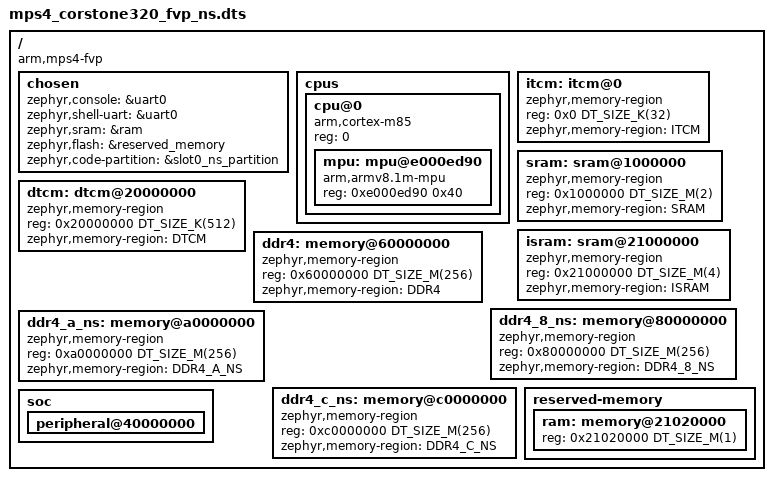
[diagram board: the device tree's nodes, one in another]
/*
 * Copyright 2025 Arm Limited and/or its affiliates <open-source-office@arm.com>
 *
 * SPDX-License-Identifier: Apache-2.0
 */

/dts-v1/;

#include <arm/armv8.1-m.dtsi>
#include <zephyr/dt-bindings/i2c/i2c.h>
#include <zephyr/dt-bindings/input/input-event-codes.h>
#include <mem.h>

#include "mps4_common_ns.dtsi"

/ {
	compatible = "arm,mps4-fvp";
	#address-cells = <1>;
	#size-cells = <1>;

	chosen {
		zephyr,console = &uart0;
		zephyr,shell-uart = &uart0;
		zephyr,sram = &ram;
		zephyr,flash = &reserved_memory;
		zephyr,code-partition = &slot0_ns_partition;
	};

	cpus {
		#address-cells = <1>;
		#size-cells = <0>;

		cpu@0 {
			device_type = "cpu";
			compatible = "arm,cortex-m85";
			reg = <0>;
			#address-cells = <1>;
			#size-cells = <1>;

			mpu: mpu@e000ed90 {
				compatible = "arm,armv8.1m-mpu";
				reg = <0xe000ed90 0x40>;
			};
		};
	};

	/* We utilize the secure addresses, if you subtract 0x10000000
	 * you'll get the non-secure alias
	 */
	itcm: itcm@0 {
		compatible = "zephyr,memory-region";
		reg = <0x0 DT_SIZE_K(32)>;
		zephyr,memory-region = "ITCM";
	};

	sram: sram@1000000 {
		compatible = "zephyr,memory-region", "mmio-sram";
		reg = <0x1000000 DT_SIZE_M(2)>;
		zephyr,memory-region = "SRAM";
	};

	dtcm: dtcm@20000000 {
		compatible = "zephyr,memory-region";
		reg = <0x20000000 DT_SIZE_K(512)>;
		zephyr,memory-region = "DTCM";
	};

	isram: sram@21000000 {
		compatible = "zephyr,memory-region", "mmio-sram";
		reg = <0x21000000 DT_SIZE_M(4)>;
		zephyr,memory-region = "ISRAM";
	};

	/* The DDR4 node and zephyr,memory-region follow the naming convention
	 * ddr4_$IDAUID_$SECURITY_FLAG except for the default region of board
	 * which is named as "DDR4" to be compatible with existing
	 * samples/tests that expect DDR4 node and region to be of the same name.
	 */
	ddr4: memory@60000000 {
		compatible = "zephyr,memory-region";
		reg = <0x60000000 DT_SIZE_M(256)>;
		zephyr,memory-region = "DDR4";
	};

	ddr4_8_ns: memory@80000000 {
		compatible = "zephyr,memory-region";
		reg = <0x80000000 DT_SIZE_M(256)>;
		zephyr,memory-region = "DDR4_8_NS";
	};

	ddr4_a_ns: memory@a0000000 {
		compatible = "zephyr,memory-region";
		reg = <0xa0000000 DT_SIZE_M(256)>;
		zephyr,memory-region = "DDR4_A_NS";
	};

	ddr4_c_ns: memory@c0000000 {
		compatible = "zephyr,memory-region";
		reg = <0xc0000000 DT_SIZE_M(256)>;
		zephyr,memory-region = "DDR4_C_NS";
	};

	reserved-memory {
		#address-cells = <1>;
		#size-cells = <1>;
		ranges;

		ram: memory@21020000 {
			reg = <0x21020000 DT_SIZE_M(1)>;
		};
	};

	soc {
		peripheral@40000000 {
			#address-cells = <1>;
			#size-cells = <1>;
			ranges = <0x0 0x40000000 0x10000000>;

			#include "mps4_common_soc_peripheral.dtsi"
		};
	};
};

#include "mps4_common.dtsi"
